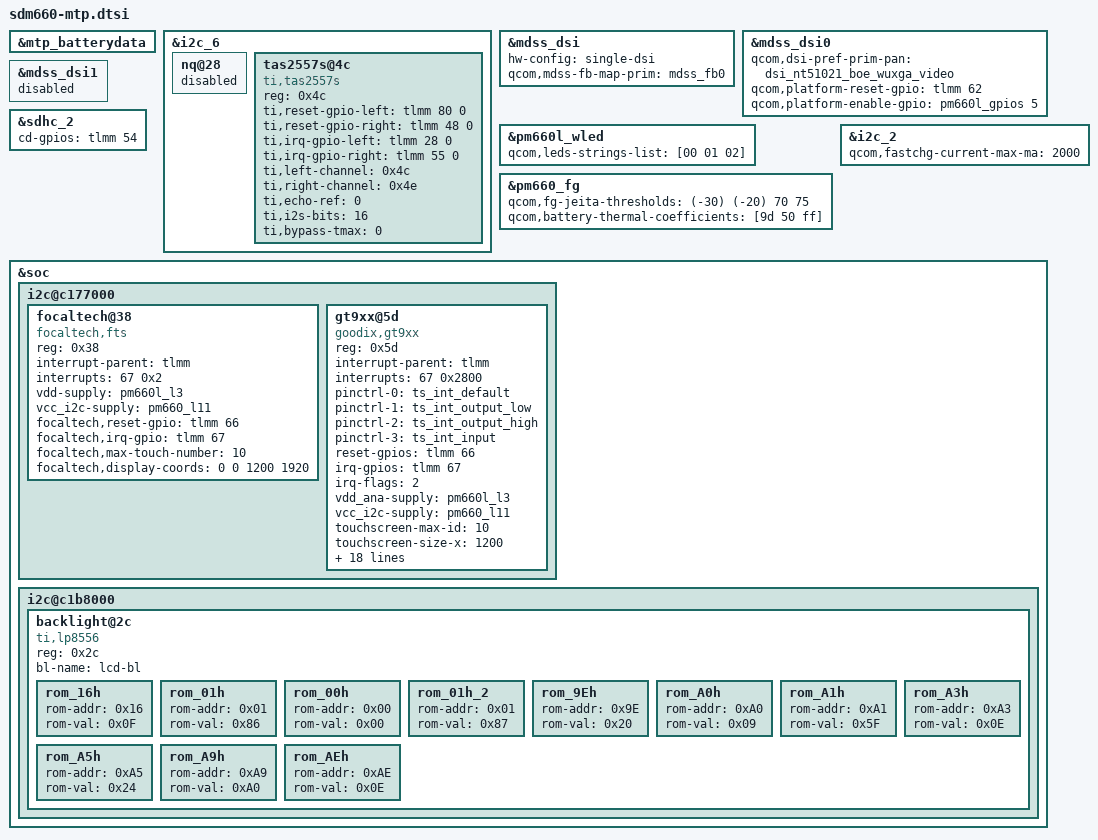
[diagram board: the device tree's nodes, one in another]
&mtp_batterydata {
	#include "batterydata-zql5018-6000mah.dtsi"
	#include "batterydata-zql6019-8600mah.dtsi"
};

&i2c_6 {
	nq@28 {
		status="disabled";
	};

	tas2557s@4c {
		compatible = "ti,tas2557s";
		reg = <0x4c>;
		ti,reset-gpio-left = <&tlmm 80 0>;
		ti,reset-gpio-right = <&tlmm 48 0>;
		ti,irq-gpio-left = <&tlmm 28 0>;
		ti,irq-gpio-right = <&tlmm 55 0>;
		ti,left-channel = <0x4c>;
		ti,right-channel = <0x4e>;
		ti,echo-ref = <0>;   /* 0, left channel; 1, right channel; 2, both */
		ti,i2s-bits = <16>;   /* support 16, 24, 32 */
		ti,bypass-tmax = <0>;   /* 0, not bypass; 1, bypass */
		status = "ok";
	};
};

&mdss_dsi {
	hw-config="single-dsi";
	qcom,mdss-fb-map-prim = <&mdss_fb0>;
};

&mdss_dsi0 {
	qcom,dsi-pref-prim-pan = <&dsi_nt51021_boe_wuxga_video>;
	qcom,platform-reset-gpio=<&tlmm 62 0>;
	qcom,platform-enable-gpio = <&pm660l_gpios 5 0>; /* VDD3V3 LDO Enable */
};

&mdss_dsi1 {
	status="disabled";
};

&pm660l_wled {
	qcom,leds-strings-list=[00 01 02];
};

&sdhc_2 {
	cd-gpios=<&tlmm 54 0x0>;
};

&pm660_fg {
	qcom,fg-jeita-thresholds = <(-30) (-20) 70 75>;
	qcom,battery-thermal-coefficients = [9d 50 ff];
};

&i2c_2 {
	qcom,fastchg-current-max-ma = <2000>;
};

&soc {
		i2c@c177000 {
		status = "ok";
		focaltech@38{
			compatible = "focaltech,fts";
			reg = <0x38>;
			interrupt-parent = <&tlmm>;
			interrupts = <67 0x2>;
			vdd-supply = <&pm660l_l3>;
			vcc_i2c-supply = <&pm660_l11>;
			focaltech,reset-gpio = <&tlmm 66 0x00>;
			focaltech,irq-gpio = <&tlmm 67 0x02>;
			focaltech,max-touch-number = <10>;
			focaltech,display-coords =  <0 0 1200 1920>;

			};
				gt9xx@5d{
			compatible = "goodix,gt9xx";
			reg = <0x5d>;
			interrupt-parent = <&tlmm>;
			interrupts = <67 0x2800>;
			pinctrl-names = "default", "int-output-low","int-output-high", "int-input";
			pinctrl-0 = <&ts_int_default>;
			pinctrl-1 = <&ts_int_output_low>;
			pinctrl-2 = <&ts_int_output_high>;
			pinctrl-3 = <&ts_int_input>;

			reset-gpios = <&tlmm 66 0x0>;
			irq-gpios = <&tlmm 67 0x2800>;
			irq-flags = <2>;

			vdd_ana-supply = <&pm660l_l3>;
			vcc_i2c-supply = <&pm660_l11>;

			touchscreen-max-id = <10>;
			touchscreen-size-x = <1200>;
			touchscreen-size-y = <1920>;
			touchscreen-max-w = <512>;
			touchscreen-max-p = <512>;
			touchscreen-key-map = <172>, <158>; /*KEY_HOMEPAGE=172, KEY_BACK=158，KEY_MENU=139*/

			goodix,slide-wakeup = <1>;
			goodix,type-a-report = <0>;
			goodix,driver-send-cfg = <1>;
			goodix,resume-in-workqueue = <0>;
			goodix,int-sync = <1>;
			goodix,swap-x2y = <0>;
			goodix,esd-protect = <1>;
			goodix,auto-update = <1>;
			goodix,auto-update-cfg = <1>;
			goodix,power-off-sleep = <0>;
			goodix,pen-suppress-finger = <0>;
			goodix,charger-cmd = <0>;
			goodix,cfg-group0 = [
                                54 B0 04 80 07 6A 35 10 11 CC
				32 0F 5A 32 2E 45 00 02 00 02
				11 12 09 14 19 1F 14 95 B5 DE
				1C 1E B0 15 33 22 00 22 44 1C
				FA FA F0 00 00 00 00 32 5A 00
				02 10 2F 8A D0 78 55 19 64 04
				A8 12 00 97 18 00 8F 1C 00 8A
				23 00 89 2D 00 89 1E 23 24 2F
				00 00 00 00 00 00 11 00 00 0C
				1E 0A 4A 04 F7 14 0A 0F 23 0F
				3C 32 0F 00 00 00 01 42 00 00
				01 14 00 01 02 03 04 05 06 07
				08 09 0A 0B 0C 0D 0E 0F 10 11
				12 13 14 15 16 17 18 19 1A FF
				FF FF 2A 29 28 27 26 25 24 23
				22 21 20 1F 1E 1D 1C 1B 19 18
				17 16 15 14 13 12 11 10 0F 0E
				0D 0C 0B 0A 09 08 07 06 05 04
				03 02 01 00 A3 01
				];
		};
		};

		i2c@c1b8000 {
		status = "ok";
		backlight@2c {
			compatible = "ti,lp8556";
			reg = <0x2c>;

			bl-name = "lcd-bl";

			rom_16h {
				rom-addr = /bits/ 8 <0x16>;
				rom-val = /bits/ 8 <0x0F>; /* 4 output LED string enabled */
				};
			rom_01h {
				rom-addr = /bits/ 8 <0x01>;
				rom-val = /bits/ 8 <0x86>;
				};
			rom_00h {
				rom-addr = /bits/ 8 <0x00>;
				rom-val = /bits/ 8 <0x00>;
				};
			rom_01h_2 {
				rom-addr = /bits/ 8 <0x01>;
				rom-val = /bits/ 8 <0x87>; /* pwm + i2c combined mode after shaper block, 12-bit */
				};
			rom_9Eh {
				rom-addr = /bits/ 8 <0x9E>;
				rom-val = /bits/ 8 <0x20>;
				};
			rom_A0h {
				rom-addr = /bits/ 8 <0xA0>;
				rom-val = /bits/ 8 <0x09>; /* max current 23.5mA */
				};
			rom_A1h {
				rom-addr = /bits/ 8 <0xA1>;
				rom-val = /bits/ 8 <0x5F>; /* max current 23.5mA */
				};
			/* remove A2=21 , fix MIC recording 10KHz noise
			rom_A2h {
				rom-addr = /bits/ 8 <0xA2>;
				rom-val = /bits/ 8 <0x21>;
				};
			*/
			rom_A3h {
				rom-addr = /bits/ 8 <0xA3>;
				rom-val = /bits/ 8 <0x0E>; /* Select brightness change transition duration 000 = 0 ms (immediate change)*/
				};
			rom_A5h {
				rom-addr = /bits/ 8 <0xA5>;
				rom-val = /bits/ 8 <0x24>;
				};
			rom_A9h {
				rom-addr = /bits/ 8 <0xA9>;
				rom-val = /bits/ 8 <0xA0>;
				};
			rom_AEh {
				rom-addr = /bits/ 8 <0xAE>;
				rom-val = /bits/ 8 <0x0E>;
				};
			};
		};

};
